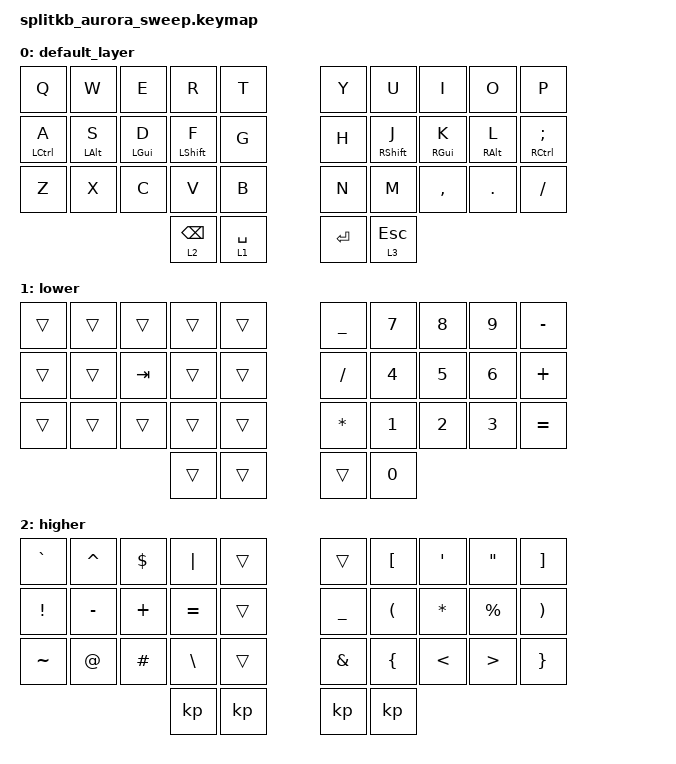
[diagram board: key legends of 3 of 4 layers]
/*
 * Copyright (c) 2022 The ZMK Contributors
 *
 * SPDX-License-Identifier: MIT
 */

#include <behaviors.dtsi>
#include <dt-bindings/zmk/bt.h>
#include <dt-bindings/zmk/keys.h>

&mt {
    //  flavor = "tap-preferred";
    // tapping-term-ms = <200>;

    tapping-term-ms = <170>;
    flavor = "tap-preferred";
    quick-tap-ms = <200>;
};

&lt {
    quick-tap-ms = <200>;
    tapping-term-ms = <170>;
};

/ {
    combos { compatible = "zmk,combos"; };

    keymap {
        compatible = "zmk,keymap";

        default_layer {
            bindings = <
&kp Q               &kp W           &kp E           &kp R             &kp T    &kp Y  &kp U              &kp I            &kp O            &kp P
&mt LEFT_CONTROL A  &mt LEFT_ALT S  &mt LEFT_GUI D  &mt LEFT_SHIFT F  &kp G    &kp H  &mt RIGHT_SHIFT J  &mt RIGHT_GUI K  &mt RIGHT_ALT L  &mt RIGHT_CONTROL SEMICOLON
&kp Z               &kp X           &kp C           &kp V             &kp B    &kp N  &kp M              &kp COMMA        &kp DOT          &kp SLASH
&lt 2 BACKSPACE     &lt 1 SPACE                                                                                           &kp ENTER        &lt 3 ESCAPE
            >;
        };

        lower {
            bindings = <
&trans  &trans  &trans   &trans  &trans    &kp UNDERSCORE  &kp N7  &kp N8  &kp N9  &kp MINUS
&trans  &trans  &kp TAB  &trans  &trans    &kp FSLH        &kp N4  &kp N5  &kp N6  &kp PLUS
&trans  &trans  &trans   &trans  &trans    &kp ASTERISK    &kp N1  &kp N2  &kp N3  &kp EQUAL
&trans  &trans                                                             &trans  &kp N0
            >;
        };

        higher {
            bindings = <
&kp GRAVE        &kp CARET    &kp DOLLAR  &kp PIPE       &trans    &trans          &kp LEFT_BRACKET      &kp SINGLE_QUOTE  &kp DOUBLE_QUOTES  &kp RIGHT_BRACKET
&kp EXCLAMATION  &kp MINUS    &kp PLUS    &kp EQUAL      &trans    &kp UNDERSCORE  &kp LEFT_PARENTHESIS  &kp ASTERISK      &kp PERCENT        &kp RIGHT_PARENTHESIS
&kp TILDE        &kp AT_SIGN  &kp HASH    &kp BACKSLASH  &trans    &kp AMPERSAND   &kp LEFT_BRACE        &kp LESS_THAN     &kp GREATER_THAN   &kp RIGHT_BRACE
&kp              &kp                                                                                                       &kp                &kp
            >;
        };

        nav {
            bindings = <
&kp LS(LG(NUMBER_3))  &kp LS(LC(LG(NUMBER_3)))  &kp LG(LC(LS(NUMBER_4)))  &kp LS(LG(NUMBER_4))  &trans    &kp LG(LEFT)  &kp LG(DOWN)  &kp LG(UP)  &kp LG(RIGHT)  &trans
&kp LS(LG(N5))        &kp C_VOLUME_DOWN         &kp C_MUTE                &kp C_VOLUME_UP       &trans    &kp LEFT      &kp DOWN      &kp UP      &kp RIGHT      &trans
&bt BT_CLR_ALL        &bt BT_SEL 0              &bt BT_SEL 1              &trans                &trans    &kp LA(LEFT)  &kp LA(DOWN)  &kp LA(UP)  &kp LA(RIGHT)  &trans
&trans                &trans                                                                                                                      &trans         &trans
            >;
        };
    };
};
